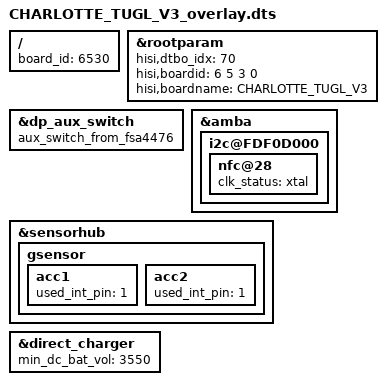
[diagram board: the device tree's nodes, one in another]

/**
 * Copyright (C) 2014 Hisilicon Ltd.
 *
 *  This program is free software; you can redistribute it and/or modify
 *  it under the terms of the GNU General Public License version 2 as
 *  publishhed by the Free Software Foundation.
 */

/dts-v1/;
/plugin/;
/include/ "CHARLOTTE_TUGL_V1_overlay.dtsi"
/include/ "CHARLOTTE_TUGL_V3_overlay_module_amba.dts"

/ {
        board_id = <6530>;
};

&rootparam {
        hisi,dtbo_idx = <70>;
    hisi,boardid = <6 5 3 0>;
    hisi,boardname = "CHARLOTTE_TUGL_V3";
};


&dp_aux_switch {
    aux_switch_from_fsa4476;
    status = "ok";
};

&amba {
    i2c@FDF0D000 {
        nfc@28 {
            clk_status ="xtal";
        };
    };
};

&sensorhub {
	gsensor {
		acc1 {
			used_int_pin =<1>;
		};
		acc2 {
			used_int_pin =<1>;
		};
	};
};
&direct_charger {
	min_dc_bat_vol = <3550>;
};
